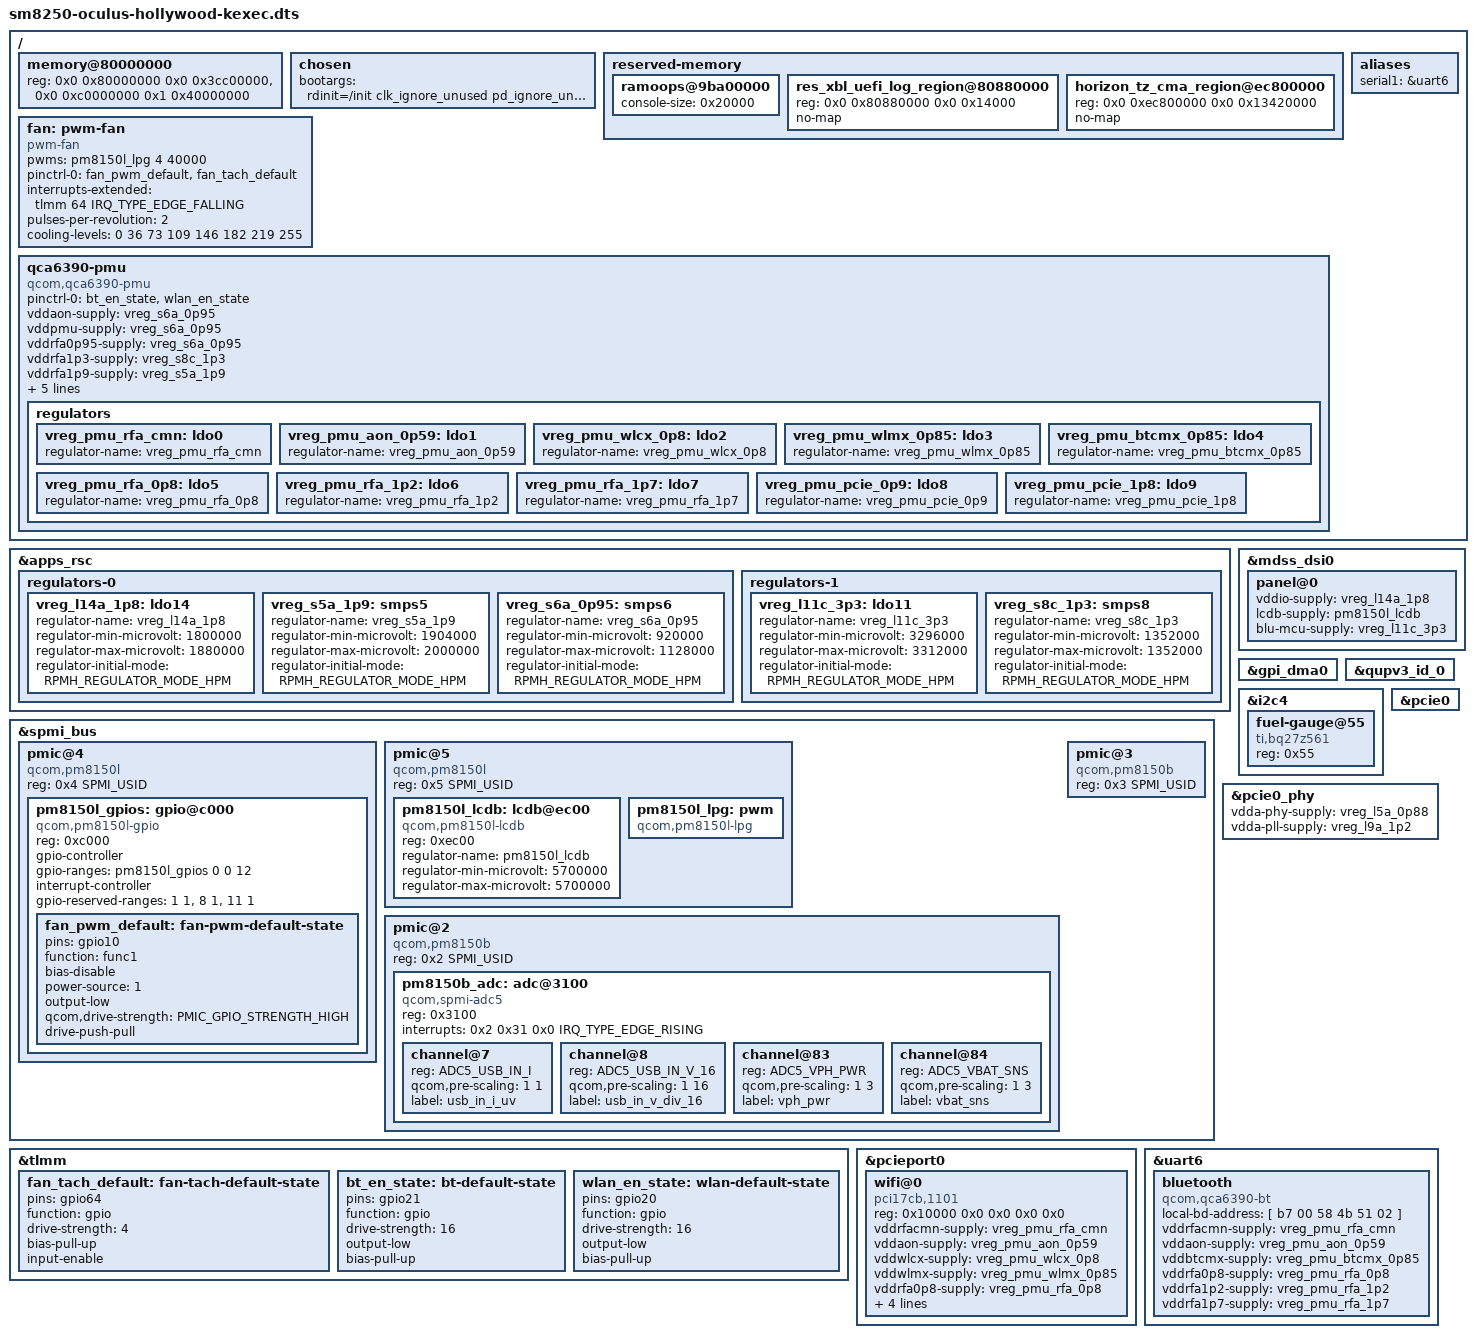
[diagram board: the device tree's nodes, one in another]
// SPDX-License-Identifier: GPL-2.0-only
/*
 * Meta Quest 2 (hollywood) kexec target over sm8250-oculus-hollywood.dts.
 * - Populates /memory@80000000 with Horizon OS's exact 6 GiB banks (ABL bypassed).
 * - Marks Horizon OS's active TZ/HYP-protected regions no-map across kexec.
 * - Matches Horizon OS's ramoops console-size (0x20000) so Horizon /sys/fs/pstore
 *   can read Linux 7.2 logs after a warm reboot/panic.
 * - Supplies kexec bootargs (panic=5 for automatic pstore-preserving warm reboot).
 */

#include <dt-bindings/pinctrl/qcom,pmic-gpio.h>
#include "sm8250-oculus-hollywood.dts"

/ {
	memory@80000000 {
		device_type = "memory";
		reg = <0x0 0x80000000 0x0 0x3cc00000>,
		      <0x0 0xc0000000 0x1 0x40000000>;
	};

	chosen {
		bootargs = "rdinit=/init clk_ignore_unused pd_ignore_unused regulator_ignore_unused panic=5 reboot=w irqchip.gicv3_pseudo_nmi=1 nmi_watchdog=panic loglevel=7 printk.devkmsg=on console=tty0 fbcon=font:TER16x32 fbcon=rotate:3 drm_client_lib.active=fbdev";
	};

	reserved-memory {
		ramoops@9ba00000 {
			console-size = <0x20000>;
		};

		res_xbl_uefi_log_region@80880000 {
			reg = <0x0 0x80880000 0x0 0x14000>;
			no-map;
		};

		/*
		 * Horizon OS reserves 0xec800000..0xffc1ffff contiguously for
		 * secure_display, user_contig, sdsp, qseecom_ta, cnss_wlan
		 * (XPU-locked to VMID_WLAN), sp, cdsp, adsp, qseecom, cma,
		 * and mailbox. Mark the entire range no-map so Linux 7.2
		 * (including SWIOTLB and buddy pages) never touches an
		 * XPU/MSA-protected physical address across kexec.
		 */
		horizon_tz_cma_region@ec800000 {
			reg = <0x0 0xec800000 0x0 0x13420000>;
			no-map;
		};
	};
};

/*
 * Display rails. We use our own panel driver (init sequence, backlight, and the three supplies below): upstream's only
 * drives enable/reset and assumes the bootloader left everything on, which is not true after a kexec.
 */
&apps_rsc {
	regulators-0 {
		vreg_l14a_1p8: ldo14 {
			regulator-name = "vreg_l14a_1p8";
			regulator-min-microvolt = <1800000>;
			regulator-max-microvolt = <1880000>;
			regulator-initial-mode = <RPMH_REGULATOR_MODE_HPM>;
		};
	};

	regulators-1 {
		vreg_l11c_3p3: ldo11 {
			regulator-name = "vreg_l11c_3p3";
			regulator-min-microvolt = <3296000>;
			regulator-max-microvolt = <3312000>;
			regulator-initial-mode = <RPMH_REGULATOR_MODE_HPM>;
		};
	};
};

&mdss_dsi0 {
	panel@0 {
		vddio-supply = <&vreg_l14a_1p8>;
		lcdb-supply = <&pm8150l_lcdb>;
		blu-mcu-supply = <&vreg_l11c_3p3>;
	};
};

&spmi_bus {
	pmic@4 {
		compatible = "qcom,pm8150l", "qcom,spmi-pmic";
		reg = <0x4 SPMI_USID>;
		#address-cells = <1>;
		#size-cells = <0>;

		pm8150l_gpios: gpio@c000 {
			compatible = "qcom,pm8150l-gpio", "qcom,spmi-gpio";
			reg = <0xc000>;
			gpio-controller;
			gpio-ranges = <&pm8150l_gpios 0 0 12>;
			#gpio-cells = <2>;
			interrupt-controller;
			#interrupt-cells = <2>;
			/* pads 2, 9 and 12 are owned by other subsystems on this board (Quest OS: gpios-disallowed) */
			gpio-reserved-ranges = <1 1>, <8 1>, <11 1>;

			/* Fan PWM pad: LPG channel at 0xbd00 (Quest OS's "pm8150l_pwm 1"; PM8150L gpios live on SID 4, its LPG on SID 5). */
			fan_pwm_default: fan-pwm-default-state {
				pins = "gpio10";
				function = "func1";
				bias-disable;
				power-source = <1>;
				output-low;
				qcom,drive-strength = <PMIC_GPIO_STRENGTH_HIGH>;
				drive-push-pull;
			};
		};
	};

	pmic@5 {
		compatible = "qcom,pm8150l", "qcom,spmi-pmic";
		reg = <0x5 SPMI_USID>;
		#address-cells = <1>;
		#size-cells = <0>;

		pm8150l_lcdb: lcdb@ec00 {
			compatible = "qcom,pm8150l-lcdb";
			reg = <0xec00>;
			regulator-name = "pm8150l_lcdb";
			regulator-min-microvolt = <5700000>;
			regulator-max-microvolt = <5700000>;
		};

		pm8150l_lpg: pwm {
			compatible = "qcom,pm8150l-lpg";
			#address-cells = <1>;
			#size-cells = <0>;
			#pwm-cells = <2>;
		};
	};
};

/ {
	/* The headset's PWM fan (25 kHz, tach on tlmm 64). pwm-fan starts it at full speed. */
	fan: pwm-fan {
		compatible = "pwm-fan";
		pwms = <&pm8150l_lpg 4 40000>;
		pinctrl-names = "default";
		pinctrl-0 = <&fan_pwm_default &fan_tach_default>;
		interrupts-extended = <&tlmm 64 IRQ_TYPE_EDGE_FALLING>;
		pulses-per-revolution = <2>;
		cooling-levels = <0 36 73 109 146 182 219 255>;
	};
};

&tlmm {
	fan_tach_default: fan-tach-default-state {
		pins = "gpio64";
		function = "gpio";
		drive-strength = <4>;
		bias-pull-up;
		input-enable;
	};

};


/* Headset battery: TI BQ27Z561 fuel gauge on QUP wrapper 0 SE4 (Horizon: qupv3_se4_i2c, address 0x55). */
&gpi_dma0 {
	status = "okay";
};

&qupv3_id_0 {
	status = "okay";
};

&i2c4 {
	status = "okay";

	fuel-gauge@55 {
		compatible = "ti,bq27z561";
		reg = <0x55>;
	};
};

/*
 * QCA6390 Wi-Fi and Bluetooth (Horizon: qcom,cnss-qca6390 + bt_qca6390). Pins from Horizon's device tree:
 * WLAN_EN gpio20, BT_EN gpio21, PCIe0 PERST gpio79 (mainline's pcie0 default), BT on QUP SE6 UART (uart6).
 * Supplies: S6A 0.95 V (aon/dig), S4A 1.8 V (io), S5A 1.9 V (rfa1/pcie), S8C 1.35 V (rfa2/pcie).
 */
&apps_rsc {
	regulators-0 {
		vreg_s5a_1p9: smps5 {
			regulator-name = "vreg_s5a_1p9";
			regulator-min-microvolt = <1904000>;
			regulator-max-microvolt = <2000000>;
			regulator-initial-mode = <RPMH_REGULATOR_MODE_HPM>;
		};

		vreg_s6a_0p95: smps6 {
			regulator-name = "vreg_s6a_0p95";
			regulator-min-microvolt = <920000>;
			regulator-max-microvolt = <1128000>;
			regulator-initial-mode = <RPMH_REGULATOR_MODE_HPM>;
		};
	};

	regulators-1 {
		vreg_s8c_1p3: smps8 {
			regulator-name = "vreg_s8c_1p3";
			regulator-min-microvolt = <1352000>;
			regulator-max-microvolt = <1352000>;
			regulator-initial-mode = <RPMH_REGULATOR_MODE_HPM>;
		};
	};
};

/ {
	qca6390-pmu {
		compatible = "qcom,qca6390-pmu";

		pinctrl-names = "default";
		pinctrl-0 = <&bt_en_state>, <&wlan_en_state>;

		vddaon-supply = <&vreg_s6a_0p95>;
		vddpmu-supply = <&vreg_s6a_0p95>;
		vddrfa0p95-supply = <&vreg_s6a_0p95>;
		vddrfa1p3-supply = <&vreg_s8c_1p3>;
		vddrfa1p9-supply = <&vreg_s5a_1p9>;
		vddpcie1p3-supply = <&vreg_s8c_1p3>;
		vddpcie1p9-supply = <&vreg_s5a_1p9>;
		vddio-supply = <&vreg_s4a_1p8>;

		wlan-enable-gpios = <&tlmm 20 GPIO_ACTIVE_HIGH>;
		bt-enable-gpios = <&tlmm 21 GPIO_ACTIVE_HIGH>;

		regulators {
			vreg_pmu_rfa_cmn: ldo0 {
				regulator-name = "vreg_pmu_rfa_cmn";
			};

			vreg_pmu_aon_0p59: ldo1 {
				regulator-name = "vreg_pmu_aon_0p59";
			};

			vreg_pmu_wlcx_0p8: ldo2 {
				regulator-name = "vreg_pmu_wlcx_0p8";
			};

			vreg_pmu_wlmx_0p85: ldo3 {
				regulator-name = "vreg_pmu_wlmx_0p85";
			};

			vreg_pmu_btcmx_0p85: ldo4 {
				regulator-name = "vreg_pmu_btcmx_0p85";
			};

			vreg_pmu_rfa_0p8: ldo5 {
				regulator-name = "vreg_pmu_rfa_0p8";
			};

			vreg_pmu_rfa_1p2: ldo6 {
				regulator-name = "vreg_pmu_rfa_1p2";
			};

			vreg_pmu_rfa_1p7: ldo7 {
				regulator-name = "vreg_pmu_rfa_1p7";
			};

			vreg_pmu_pcie_0p9: ldo8 {
				regulator-name = "vreg_pmu_pcie_0p9";
			};

			vreg_pmu_pcie_1p8: ldo9 {
				regulator-name = "vreg_pmu_pcie_1p8";
			};
		};
	};
};

&pcie0 {
	status = "okay";
};

&pcie0_phy {
	status = "okay";
	vdda-phy-supply = <&vreg_l5a_0p88>;
	vdda-pll-supply = <&vreg_l9a_1p2>;
};

&pcieport0 {
	wifi@0 {
		compatible = "pci17cb,1101";
		reg = <0x10000 0x0 0x0 0x0 0x0>;

		vddrfacmn-supply = <&vreg_pmu_rfa_cmn>;
		vddaon-supply = <&vreg_pmu_aon_0p59>;
		vddwlcx-supply = <&vreg_pmu_wlcx_0p8>;
		vddwlmx-supply = <&vreg_pmu_wlmx_0p85>;
		vddrfa0p8-supply = <&vreg_pmu_rfa_0p8>;
		vddrfa1p2-supply = <&vreg_pmu_rfa_1p2>;
		vddrfa1p7-supply = <&vreg_pmu_rfa_1p7>;
		vddpcie0p9-supply = <&vreg_pmu_pcie_0p9>;
		vddpcie1p8-supply = <&vreg_pmu_pcie_1p8>;
	};
};

&uart6 {
	status = "okay";

	bluetooth {
		compatible = "qcom,qca6390-bt";

		/* The chip has no address of its own; this is a locally administered one (02:51:4b:58:00:b7), LSB first. */
		local-bd-address = [ b7 00 58 4b 51 02 ];

		vddrfacmn-supply = <&vreg_pmu_rfa_cmn>;
		vddaon-supply = <&vreg_pmu_aon_0p59>;
		vddbtcmx-supply = <&vreg_pmu_btcmx_0p85>;
		vddrfa0p8-supply = <&vreg_pmu_rfa_0p8>;
		vddrfa1p2-supply = <&vreg_pmu_rfa_1p2>;
		vddrfa1p7-supply = <&vreg_pmu_rfa_1p7>;
	};
};

&tlmm {
	bt_en_state: bt-default-state {
		pins = "gpio21";
		function = "gpio";
		drive-strength = <16>;
		output-low;
		bias-pull-up;
	};

	wlan_en_state: wlan-default-state {
		pins = "gpio20";
		function = "gpio";
		drive-strength = <16>;
		output-low;
		bias-pull-up;
	};
};

/* Bluetooth's UART needs a serial alias, or qcom_geni_serial refuses it ("Invalid line -19"). */
/ {
	aliases {
		serial1 = &uart6;
	};
};

/*
 * PM8150B (battery charger SMB5, USB Type-C / PD PHY, fuel gauge) at SPMI addresses 2 and 3. Our tree never declared it, so the kernel could not see
 * the charger at all. Bare nodes for now: they only make the PMIC's registers readable (debugfs regmap "0-02", "0-03") to find out why the headset does
 * not charge under Linux; no child devices are enabled.
 */
&spmi_bus {
	pmic@2 {
		compatible = "qcom,pm8150b", "qcom,spmi-pmic";
		reg = <0x2 SPMI_USID>;
		#address-cells = <1>;
		#size-cells = <0>;

		/* USB input voltage/current and battery/system rail voltages: what the charger actually sees (IIO, /sys/bus/iio/devices). */
		pm8150b_adc: adc@3100 {
			compatible = "qcom,spmi-adc5";
			reg = <0x3100>;
			#address-cells = <1>;
			#size-cells = <0>;
			#io-channel-cells = <1>;
			interrupts = <0x2 0x31 0x0 IRQ_TYPE_EDGE_RISING>;

			channel@7 {
				reg = <ADC5_USB_IN_I>;
				qcom,pre-scaling = <1 1>;
				label = "usb_in_i_uv";
			};

			channel@8 {
				reg = <ADC5_USB_IN_V_16>;
				qcom,pre-scaling = <1 16>;
				label = "usb_in_v_div_16";
			};

			channel@83 {
				reg = <ADC5_VPH_PWR>;
				qcom,pre-scaling = <1 3>;
				label = "vph_pwr";
			};

			channel@84 {
				reg = <ADC5_VBAT_SNS>;
				qcom,pre-scaling = <1 3>;
				label = "vbat_sns";
			};
		};
	};

	pmic@3 {
		compatible = "qcom,pm8150b", "qcom,spmi-pmic";
		reg = <0x3 SPMI_USID>;
		#address-cells = <1>;
		#size-cells = <0>;
	};
};
